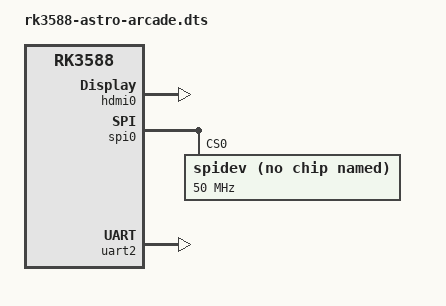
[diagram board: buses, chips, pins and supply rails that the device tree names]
/dts-v1/;
/plugin/;

/ {
    compatible = "rockchip,rk3588";

    fragment@0 {
        target-path = "/reserved-memory";
        __overlay__ {
            #address-cells = <2>;
            #size-cells = <2>;

            linux,cma {
                compatible = "shared-dma-pool";
                reusable;
                size = <0x0 0x20000000>; /* 512MB CMA */
                linux,cma-default;
                alloc-ranges = <0x0 0x80000000 0x0 0x40000000>;
            };
        };
    };

    fragment@1 {
        target = <&pcie30phy>;
        __overlay__ {
            status = "disabled";
        };
    };

    fragment@2 {
        target = <&sata0>;
        __overlay__ {
            status = "disabled";
        };
    };

    fragment@3 {
        target = <&hdmi0>;
        __overlay__ {
            status = "okay";
            rockchip,phy-table = <
                0x00 0x110000 0x00 0x00 0x00 0x00 0x00 0x00
            >;
        };
    };

    fragment@4 {
        target = <&spi0>;
        __overlay__ {
            status = "okay";
            #address-cells = <1>;
            #size-cells = <0>;
            spidev@0 {
                compatible = "rohm,dh2228fv";
                reg = <0>;
                spi-max-frequency = <50000000>;
            };
        };
    };

    fragment@5 {
        target = <&uart2>;
        __overlay__ {
            status = "okay";
            pinctrl-names = "default";
            pinctrl-0 = <&uart2m0_xfer>;
        };
    };
};
